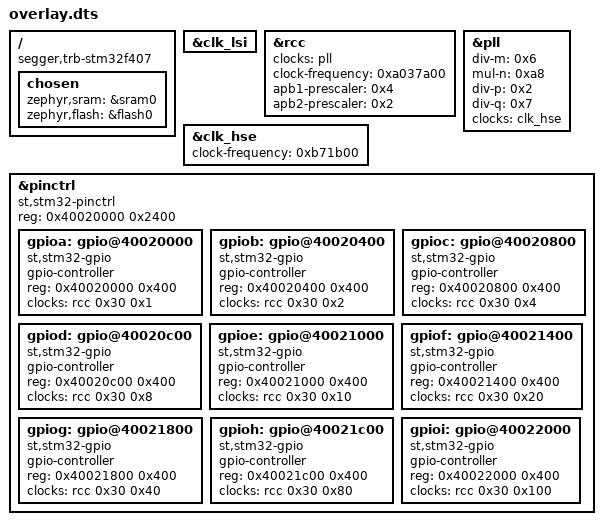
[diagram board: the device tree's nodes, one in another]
/ {
	compatible = "segger,trb-stm32f407";
	chosen {
		zephyr,sram = &sram0;
		zephyr,flash = &flash0;
	};
};
&clk_lsi{
	status = "okay";
};
&rcc{
	clocks = < &pll >;
	clock-frequency = < 0xa037a00 >;
	apb1-prescaler = < 0x4 >;
	apb2-prescaler = < 0x2 >;
};
&pll{
	status = "okay";
	div-m = < 0x6 >;
	mul-n = < 0xa8 >;
	div-p = < 0x2 >;
	div-q = < 0x7 >;
	clocks = < &clk_hse >;
};
&clk_hse{
	status = "okay";
	clock-frequency = < 0xb71b00 >;
};
&pinctrl{
	compatible = "st,stm32-pinctrl";
	#address-cells = < 0x1 >;
	#size-cells = < 0x1 >;
	reg = < 0x40020000 0x2400 >;
	gpioa: gpio@40020000 {
		compatible = "st,stm32-gpio";
		gpio-controller;
		#gpio-cells = < 0x2 >;
		reg = < 0x40020000 0x400 >;
		clocks = < &rcc 0x30 0x1 >;
	};
	gpiob: gpio@40020400 {
		compatible = "st,stm32-gpio";
		gpio-controller;
		#gpio-cells = < 0x2 >;
		reg = < 0x40020400 0x400 >;
		clocks = < &rcc 0x30 0x2 >;
	};
	gpioc: gpio@40020800 {
		compatible = "st,stm32-gpio";
		gpio-controller;
		#gpio-cells = < 0x2 >;
		reg = < 0x40020800 0x400 >;
		clocks = < &rcc 0x30 0x4 >;
	};
	gpiod: gpio@40020c00 {
		compatible = "st,stm32-gpio";
		gpio-controller;
		#gpio-cells = < 0x2 >;
		reg = < 0x40020c00 0x400 >;
		clocks = < &rcc 0x30 0x8 >;
	};
	gpioe: gpio@40021000 {
		compatible = "st,stm32-gpio";
		gpio-controller;
		#gpio-cells = < 0x2 >;
		reg = < 0x40021000 0x400 >;
		clocks = < &rcc 0x30 0x10 >;
	};
	gpiof: gpio@40021400 {
		compatible = "st,stm32-gpio";
		gpio-controller;
		#gpio-cells = < 0x2 >;
		reg = < 0x40021400 0x400 >;
		clocks = < &rcc 0x30 0x20 >;
	};
	gpiog: gpio@40021800 {
		compatible = "st,stm32-gpio";
		gpio-controller;
		#gpio-cells = < 0x2 >;
		reg = < 0x40021800 0x400 >;
		clocks = < &rcc 0x30 0x40 >;
	};
	gpioh: gpio@40021c00 {
		compatible = "st,stm32-gpio";
		gpio-controller;
		#gpio-cells = < 0x2 >;
		reg = < 0x40021c00 0x400 >;
		clocks = < &rcc 0x30 0x80 >;
	};
	gpioi: gpio@40022000 {
		compatible = "st,stm32-gpio";
		gpio-controller;
		#gpio-cells = < 0x2 >;
		reg = < 0x40022000 0x400 >;
		clocks = < &rcc 0x30 0x100 >;
	};
};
